# cc13x2_cc26x2 register map
File version: 2.1
CPU: CM4 r0p1, little endian, MPU, FPU, 3 interrupt priority bits
Registers are 32-bit, read-write, reset 0x0 unless marked. A register's access mark holds for its fields unless they carry their own. Offsets are from the block's base; [hi:lo] are bit positions; {n}, {i} and the like mark numbered series; 'fields as' and 'values as' point back to an identical list.

## AUX_DDI0_OSC — Digital to Digital Interface his is a generic module for handling register information between digital core and and digital subchips within the analog domain. o see the actual contents connected on the analog side, please see: DI0: DDI_0_OSC:DDI_0_OSC
Base 0x400CA000
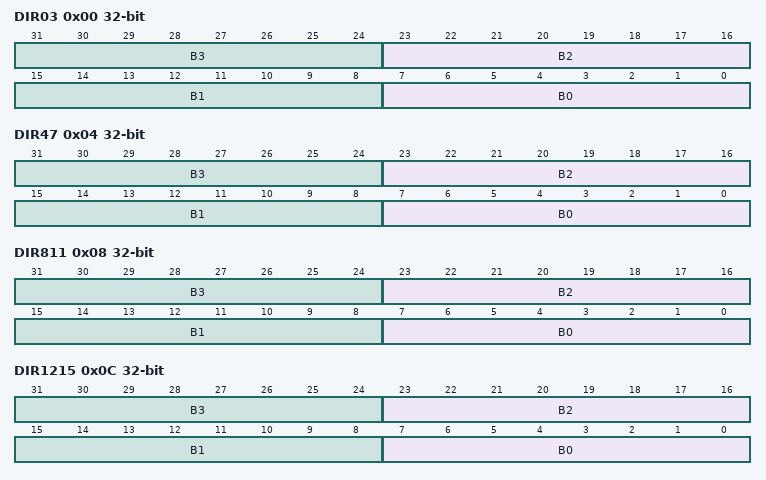
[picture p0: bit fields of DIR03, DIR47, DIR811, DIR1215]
0x00 DIR03 — Direct Access for DDI Byte Offsets 0 to 3
  [8n+7:8n] B{n} (n=0..3)
0x04 DIR47 — Direct Access for DDI Byte Offsets 4 to 7
  [8n+7:8n] B{n} (n=0..3)
0x08 DIR811 — Direct Access for DDI Byte Offsets 8 to 11
  [8n+7:8n] B{n} (n=0..3)
0x0C DIR1215 — Direct Access for DDI Byte Offsets 12 to 15
  [8n+7:8n] B{n} (n=0..3)
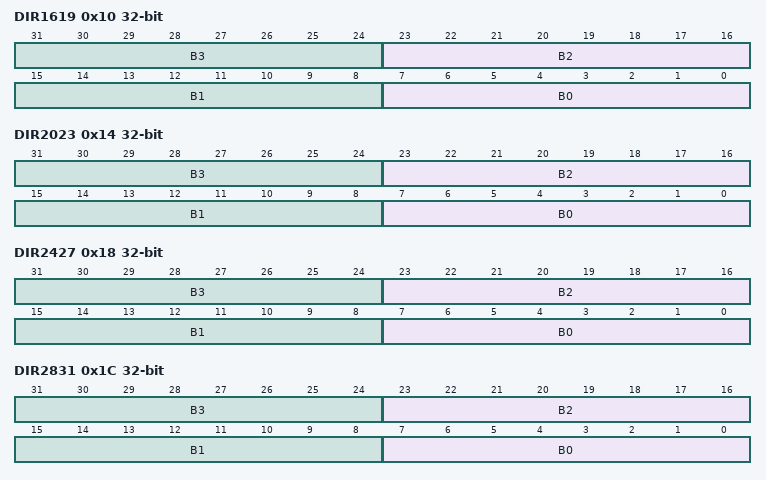
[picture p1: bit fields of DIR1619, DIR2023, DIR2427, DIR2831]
0x10 DIR1619 — Direct Access for DDI Byte Offsets 16 to 19
  [8n+7:8n] B{n} (n=0..3)
0x14 DIR2023 — Direct Access for DDI Byte Offsets 20 to 23
  [8n+7:8n] B{n} (n=0..3)
0x18 DIR2427 — Direct Access for DDI Byte Offsets 24 to 27
  [8n+7:8n] B{n} (n=0..3)
0x1C DIR2831 — Direct Access for DDI Byte Offsets 28 to 31
  [8n+7:8n] B{n} (n=0..3)
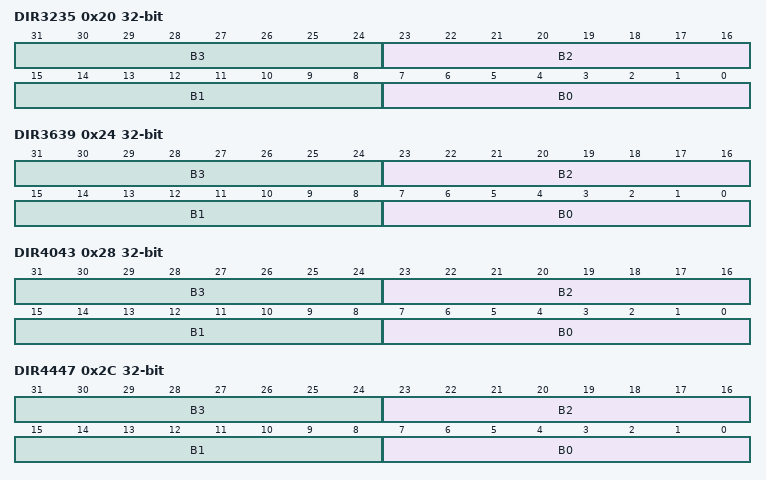
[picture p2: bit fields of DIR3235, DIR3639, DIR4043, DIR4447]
0x20 DIR3235 — Direct Access for DDI Byte Offsets 32 to 35
  [8n+7:8n] B{n} (n=0..3)
0x24 DIR3639 — Direct Access for DDI Byte Offsets 36 to 39
  [8n+7:8n] B{n} (n=0..3)
0x28 DIR4043 — Direct Access for DDI Byte Offsets 40 to 43
  [8n+7:8n] B{n} (n=0..3)
0x2C DIR4447 — Direct Access for DDI Byte Offsets 44 to 47
  [8n+7:8n] B{n} (n=0..3)
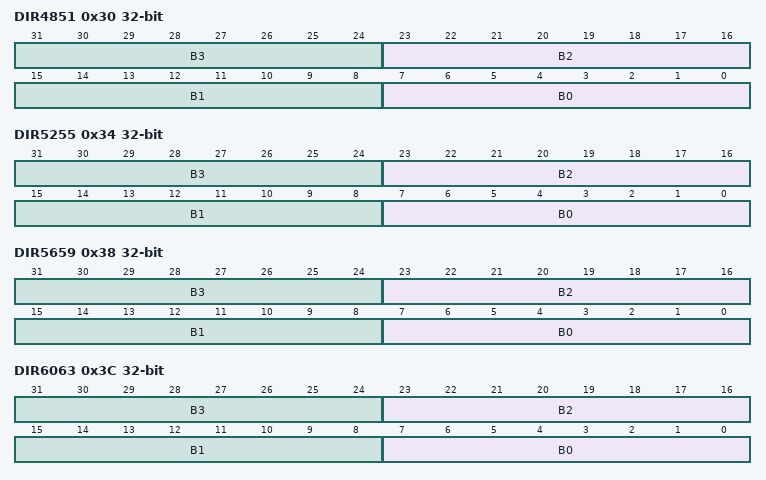
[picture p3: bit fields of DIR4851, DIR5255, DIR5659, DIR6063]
0x30 DIR4851 — Direct Access for DDI Byte Offsets 48 to 51
  [8n+7:8n] B{n} (n=0..3)
0x34 DIR5255 — Direct Access for DDI Byte Offsets 52 to 55
  [8n+7:8n] B{n} (n=0..3)
0x38 DIR5659 — Direct Access for DDI Byte Offsets 56 to 59
  [8n+7:8n] B{n} (n=0..3)
0x3C DIR6063 — Direct Access for DDI Byte Offsets 60 to 63
  [8n+7:8n] B{n} (n=0..3)
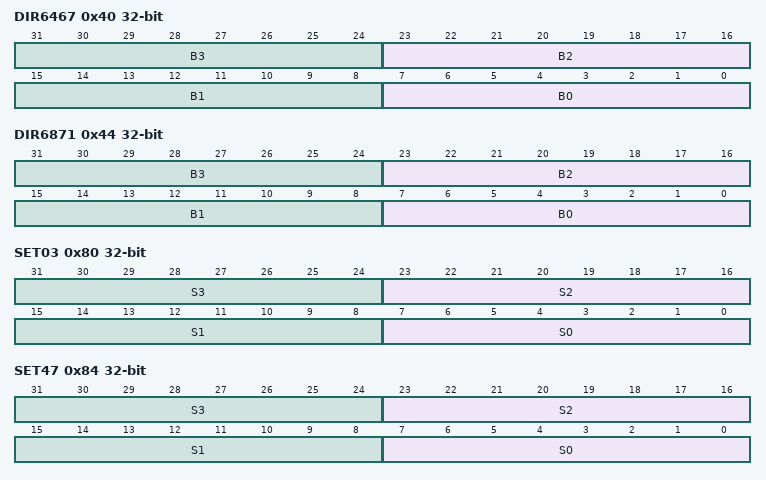
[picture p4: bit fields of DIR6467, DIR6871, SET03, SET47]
0x40 DIR6467 — Direct Access for DDI Byte Offsets 64 to 67
  [8n+7:8n] B{n} (n=0..3)
0x44 DIR6871 — Direct Access for DDI Byte Offsets 68 to 71
  [8n+7:8n] B{n} (n=0..3)
0x80 SET03 wo — Set for DDI Byte Offsets 0 to 3
  [8n+7:8n] S{n} (n=0..3)
0x84 SET47 wo — Set for DDI Byte Offsets 4 to 7
  [8n+7:8n] S{n} (n=0..3)
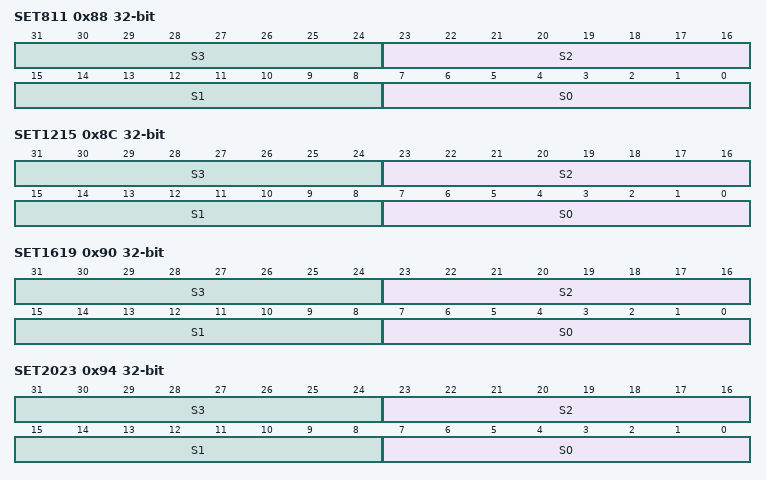
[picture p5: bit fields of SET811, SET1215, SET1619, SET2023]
0x88 SET811 wo — Set for DDI Byte Offsets 8 to 11
  [8n+7:8n] S{n} (n=0..3)
0x8C SET1215 wo — Set for DDI Byte Offsets 12 to 15
  [8n+7:8n] S{n} (n=0..3)
0x90 SET1619 wo — Set for DDI Byte Offsets 16 to 19
  [8n+7:8n] S{n} (n=0..3)
0x94 SET2023 wo — Set for DDI Byte Offsets 20 to 23
  [8n+7:8n] S{n} (n=0..3)
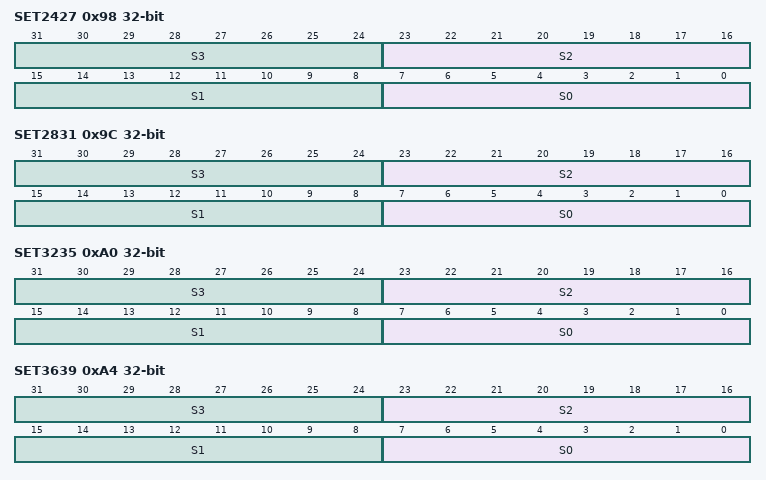
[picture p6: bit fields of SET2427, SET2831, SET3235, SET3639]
0x98 SET2427 wo — Set for DDI Byte Offsets 24 to 27
  [8n+7:8n] S{n} (n=0..3)
0x9C SET2831 wo — Set for DDI Byte Offsets 28 to 31
  [8n+7:8n] S{n} (n=0..3)
0xA0 SET3235 wo — Set for DDI Byte Offsets 32 to 35
  [8n+7:8n] S{n} (n=0..3)
0xA4 SET3639 wo — Set for DDI Byte Offsets 36 to 39
  [8n+7:8n] S{n} (n=0..3)
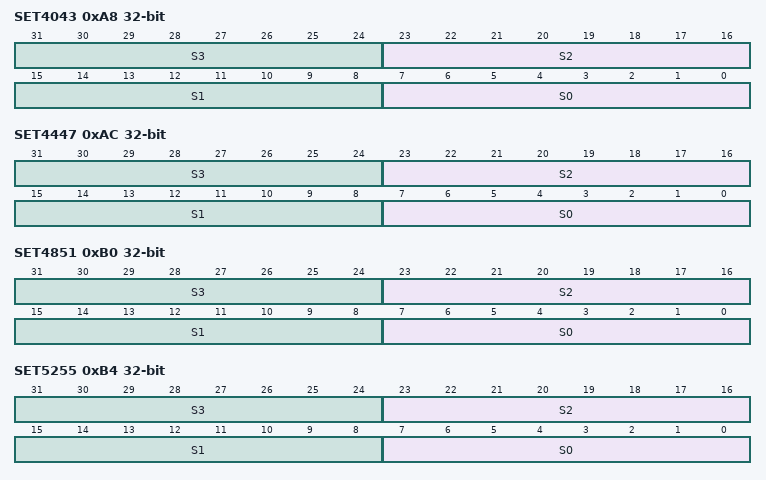
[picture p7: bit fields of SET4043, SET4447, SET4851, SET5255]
0xA8 SET4043 wo — Set for DDI Byte Offsets 40 to 43
  [8n+7:8n] S{n} (n=0..3)
0xAC SET4447 wo — Set for DDI Byte Offsets 44 to 47
  [8n+7:8n] S{n} (n=0..3)
0xB0 SET4851 wo — Set for DDI Byte Offsets 48 to 51
  [8n+7:8n] S{n} (n=0..3)
0xB4 SET5255 wo — Set for DDI Byte Offsets 52 to 55
  [8n+7:8n] S{n} (n=0..3)
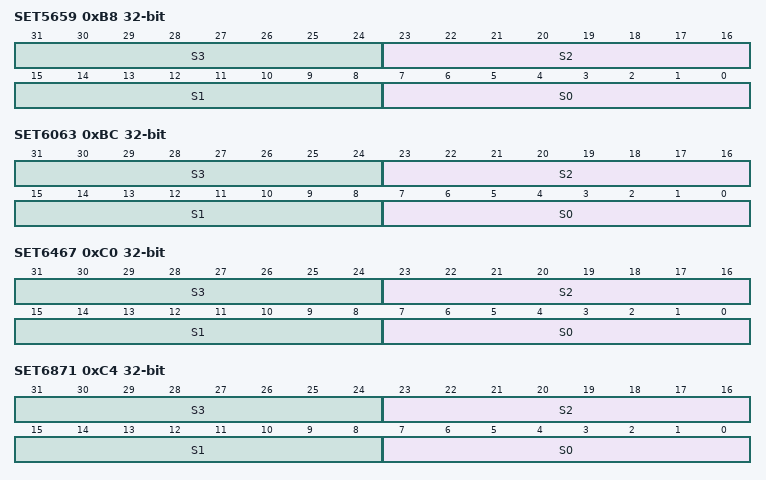
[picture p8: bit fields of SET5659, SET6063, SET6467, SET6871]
0xB8 SET5659 wo — Set for DDI Byte Offsets 56 to 59
  [8n+7:8n] S{n} (n=0..3)
0xBC SET6063 wo — Set for DDI Byte Offsets 60 to 63
  [8n+7:8n] S{n} (n=0..3)
0xC0 SET6467 wo — Set for DDI Byte Offsets 64 to 67
  [8n+7:8n] S{n} (n=0..3)
0xC4 SET6871 wo — Set for DDI Byte Offsets 68 to 71
  [8n+7:8n] S{n} (n=0..3)
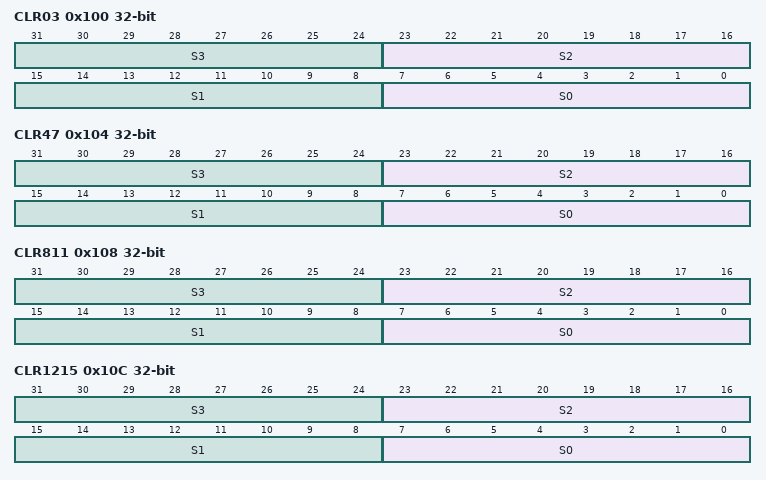
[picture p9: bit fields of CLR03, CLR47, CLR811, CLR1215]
0x100 CLR03 wo — Clear for DDI Byte Offsets 0 to 3
  [8n+7:8n] S{n} (n=0..3)
0x104 CLR47 wo — Clear for DDI Byte Offsets 4 to 7
  [8n+7:8n] S{n} (n=0..3)
0x108 CLR811 wo — Clear for DDI Byte Offsets 8 to 11
  [8n+7:8n] S{n} (n=0..3)
0x10C CLR1215 wo — Clear for DDI Byte Offsets 12 to 15
  [8n+7:8n] S{n} (n=0..3)
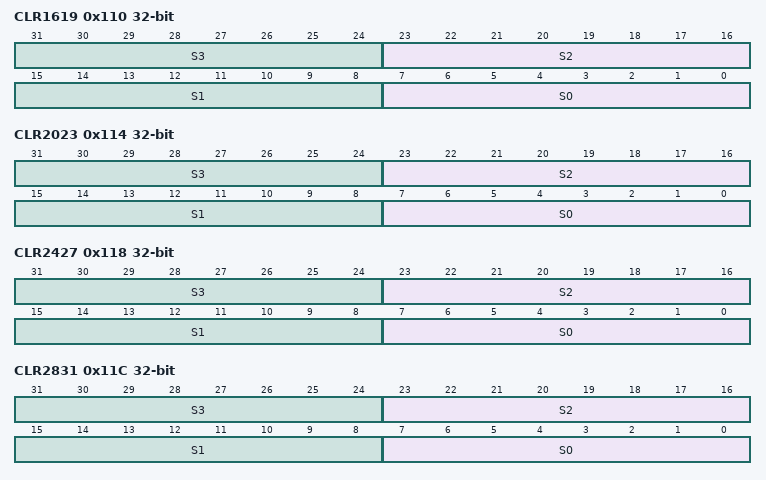
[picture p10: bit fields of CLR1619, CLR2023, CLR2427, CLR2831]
0x110 CLR1619 wo — Clear for DDI Byte Offsets 16 to 19
  [8n+7:8n] S{n} (n=0..3)
0x114 CLR2023 wo — Clear for DDI Byte Offsets 20 to 23
  [8n+7:8n] S{n} (n=0..3)
0x118 CLR2427 wo — Clear for DDI Byte Offsets 24 to 27
  [8n+7:8n] S{n} (n=0..3)
0x11C CLR2831 wo — Clear for DDI Byte Offsets 28 to 31
  [8n+7:8n] S{n} (n=0..3)
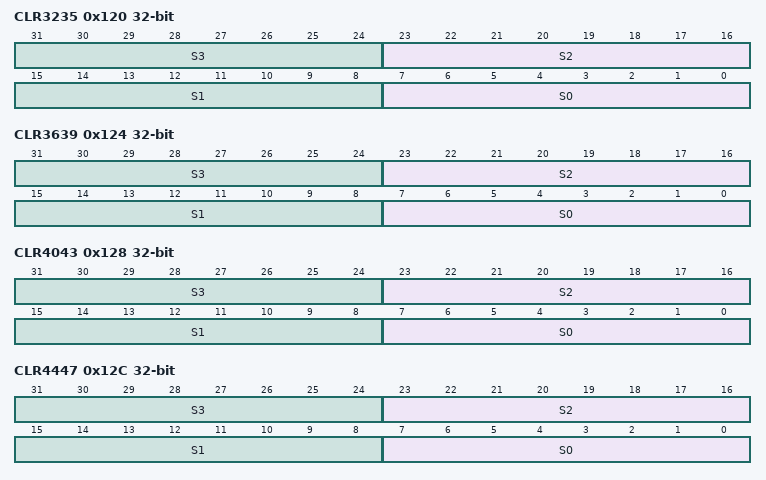
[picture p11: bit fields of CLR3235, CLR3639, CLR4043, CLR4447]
0x120 CLR3235 wo — Clear for DDI Byte Offsets 32 to 35
  [8n+7:8n] S{n} (n=0..3)
0x124 CLR3639 wo — Clear for DDI Byte Offsets 36 to 39
  [8n+7:8n] S{n} (n=0..3)
0x128 CLR4043 wo — Clear for DDI Byte Offsets 40 to 43
  [8n+7:8n] S{n} (n=0..3)
0x12C CLR4447 wo — Clear for DDI Byte Offsets 44 to 47
  [8n+7:8n] S{n} (n=0..3)
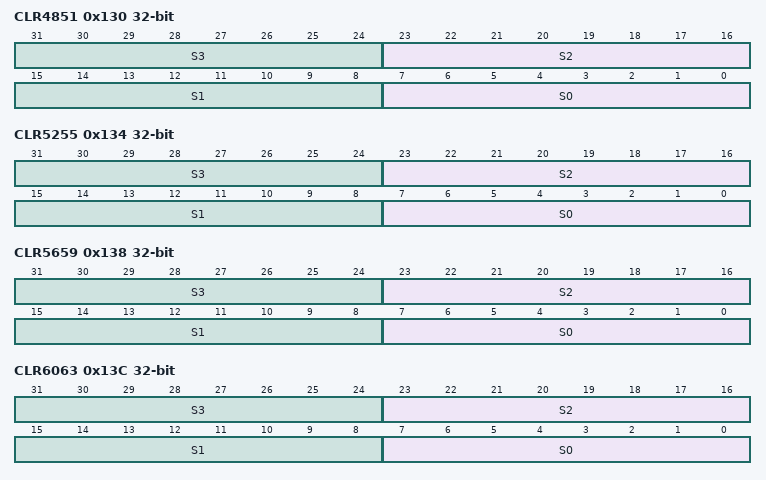
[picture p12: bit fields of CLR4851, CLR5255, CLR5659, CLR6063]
0x130 CLR4851 wo — Clear for DDI Byte Offsets 48 to 51
  [8n+7:8n] S{n} (n=0..3)
0x134 CLR5255 wo — Clear for DDI Byte Offsets 52 to 55
  [8n+7:8n] S{n} (n=0..3)
0x138 CLR5659 wo — Clear for DDI Byte Offsets 56 to 59
  [8n+7:8n] S{n} (n=0..3)
0x13C CLR6063 wo — Clear for DDI Byte Offsets 60 to 63
  [8n+7:8n] S{n} (n=0..3)
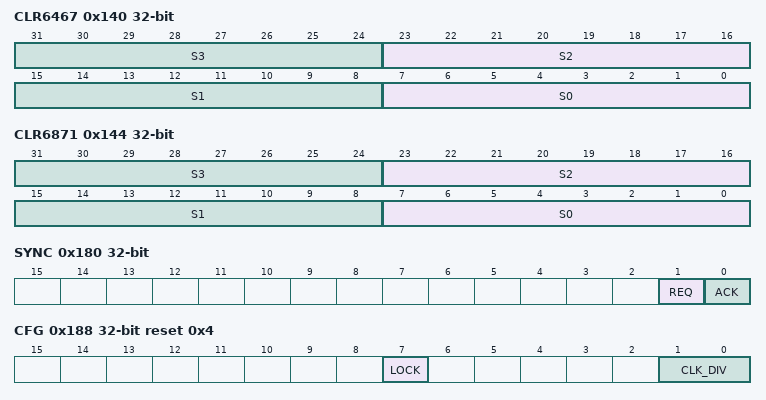
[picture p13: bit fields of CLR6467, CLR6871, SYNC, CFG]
0x140 CLR6467 wo — Clear for DDI Byte Offsets 64 to 67
  [8n+7:8n] S{n} (n=0..3)
0x144 CLR6871 wo — Clear for DDI Byte Offsets 68 to 71
  [8n+7:8n] S{n} (n=0..3)
0x180 SYNC — Internal. Only to be used through TI provided API.
  [1] REQ, [0] ACK
0x188 CFG reset 0x4 — Internal. Only to be used through TI provided API.
  [7] LOCK, [1:0] CLK_DIV
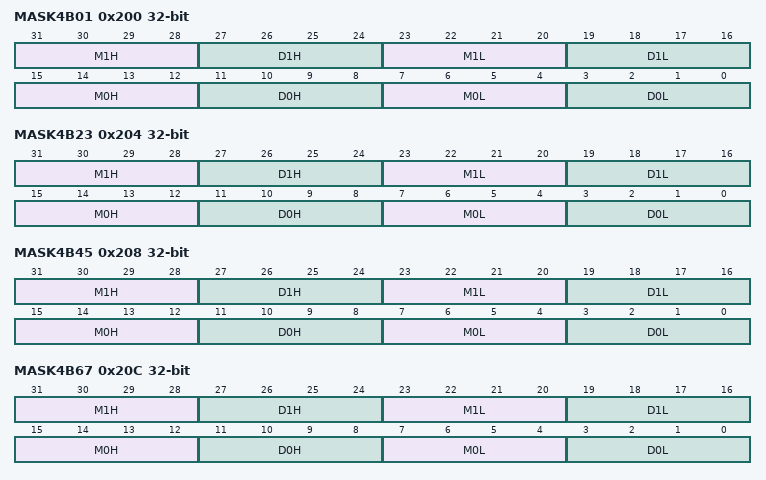
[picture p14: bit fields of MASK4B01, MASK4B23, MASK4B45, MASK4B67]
0x200 MASK4B01 wo — Masked Access (4m/4d), Byte Offsets 0 and 1
  [31:28] M1H, [27:24] D1H, [23:20] M1L, [19:16] D1L, [15:12] M0H, [11:8] D0H, [7:4] M0L, [3:0] D0L
0x204 MASK4B23 wo — Masked Access (4m/4d), Byte Offsets 2 and 3
  fields as MASK4B01
0x208 MASK4B45 wo — Masked Access (4m/4d), Byte Offsets 4 and 5
  fields as MASK4B01
0x20C MASK4B67 wo — Masked Access (4m/4d), Byte Offsets 6 and 7
  fields as MASK4B01
0x210 MASK4B89 wo — Masked Access (4m/4d), Byte Offsets 8 and 9
  fields as MASK4B01
0x214 MASK4B1011 wo — Masked Access (4m/4d), Byte Offsets 10 and 11
  fields as MASK4B01
0x218 MASK4B1213 wo — Masked Access (4m/4d), Byte Offsets 12 and 13
  fields as MASK4B01
0x21C MASK4B1415 wo — Masked Access (4m/4d), Byte Offsets 14 and 15
  fields as MASK4B01
0x220 MASK4B1617 wo — Masked Access (4m/4d), Byte Offsets 16 and 17
  fields as MASK4B01
0x224 MASK4B1819 wo — Masked Access (4m/4d), Byte Offsets 18 and 19
  fields as MASK4B01
0x228 MASK4B2021 wo — Masked Access (4m/4d), Byte Offsets 20 and 21
  fields as MASK4B01
0x22C MASK4B2223 wo — Masked Access (4m/4d), Byte Offsets 22 and 23
  fields as MASK4B01
0x230 MASK4B2425 wo — Masked Access (4m/4d), Byte Offsets 24 and 25
  fields as MASK4B01
0x234 MASK4B2627 wo — Masked Access (4m/4d), Byte Offsets 26 and 27
  fields as MASK4B01
0x238 MASK4B2829 wo — Masked Access (4m/4d), Byte Offsets 28 and 29
  fields as MASK4B01
0x23C MASK4B3031 wo — Masked Access (4m/4d), Byte Offsets 30 and 31
  fields as MASK4B01
0x240 MASK4B3233 wo — Masked Access (4m/4d), Byte Offsets 32 and 33
  fields as MASK4B01
0x244 MASK4B3435 wo — Masked Access (4m/4d), Byte Offsets 34 and 35
  fields as MASK4B01
0x248 MASK4B3637 wo — Masked Access (4m/4d), Byte Offsets 36 and 37
  fields as MASK4B01
0x24C MASK4B3839 wo — Masked Access (4m/4d), Byte Offsets 38 and 39
  fields as MASK4B01
0x250 MASK4B4041 wo — Masked Access (4m/4d), Byte Offsets 40 and 41
  fields as MASK4B01
0x254 MASK4B4243 wo — Masked Access (4m/4d), Byte Offsets 42 and 43
  fields as MASK4B01
0x258 MASK4B4445 wo — Masked Access (4m/4d), Byte Offsets 44 and 45
  fields as MASK4B01
0x25C MASK4B4647 wo — Masked Access (4m/4d), Byte Offsets 46 and 47
  fields as MASK4B01
0x260 MASK4B4849 wo — Masked Access (4m/4d), Byte Offsets 48 and 49
  fields as MASK4B01
0x264 MASK4B5051 wo — Masked Access (4m/4d), Byte Offsets 50 and 51
  fields as MASK4B01
0x268 MASK4B5253 wo — Masked Access (4m/4d), Byte Offsets 52 and 53
  fields as MASK4B01
0x26C MASK4B5455 wo — Masked Access (4m/4d), Byte Offsets 54 and 55
  fields as MASK4B01
0x270 MASK4B5657 wo — Masked Access (4m/4d), Byte Offsets 56 and 57
  fields as MASK4B01
0x274 MASK4B5859 wo — Masked Access (4m/4d), Byte Offsets 58 and 59
  fields as MASK4B01
0x278 MASK4B6061 wo — Masked Access (4m/4d), Byte Offsets 60 and 61
  fields as MASK4B01
0x27C MASK4B6263 wo — Masked Access (4m/4d), Byte Offsets 62 and 63
  fields as MASK4B01
0x280 MASK4B6465 wo — Masked Access (4m/4d), Byte Offsets 64 and 65
  fields as MASK4B01
0x284 MASK4B6667 wo — Masked Access (4m/4d), Byte Offsets 66 and 67
  fields as MASK4B01
0x288 MASK4B6869 wo — Masked Access (4m/4d), Byte Offsets 68 and 69
  fields as MASK4B01
0x28C MASK4B7071 wo — Masked Access (4m/4d), Byte Offsets 70 and 71
  fields as MASK4B01
0x300 MASK8B01 wo — Masked Access (8m/8d), Byte Offsets 0 and 1
  [31:24] M1, [23:16] D1, [15:8] M0, [7:0] D0
0x304 MASK8B23 wo — Masked Access (8m/8d), Byte Offsets 2 and 3
  [31:24] M1, [23:16] D1, [15:8] M0, [7:0] D0
0x308 MASK8B45 wo — Masked Access (8m/8d), Byte Offsets 4 and 5
  [31:24] M1, [23:16] D1, [15:8] M0, [7:0] D0
0x30C MASK8B67 wo — Masked Access (8m/8d), Byte Offsets 6 and 7
  [31:24] M1, [23:16] D1, [15:8] M0, [7:0] D0
0x310 MASK8B89 wo — Masked Access (8m/8d), Byte Offsets 8 and 9
  [31:24] M1, [23:16] D1, [15:8] M0, [7:0] D0
0x314 MASK8B1011 wo — Masked Access (8m/8d), Byte Offsets 10 and 11
  [31:24] M1, [23:16] D1, [15:8] M0, [7:0] D0
0x318 MASK8B1213 wo — Masked Access (8m/8d), Byte Offsets 12 and 13
  [31:24] M1, [23:16] D1, [15:8] M0, [7:0] D0
0x31C MASK8B1415 wo — Masked Access (8m/8d), Byte Offsets 14 and 15
  [31:24] M1, [23:16] D1, [15:8] M0, [7:0] D0
0x320 MASK8B1617 wo — Masked Access (8m/8d), Byte Offsets 16 and 17
  [31:24] M1, [23:16] D1, [15:8] M0, [7:0] D0
0x324 MASK8B1819 wo — Masked Access (8m/8d), Byte Offsets 18 and 19
  [31:24] M1, [23:16] D1, [15:8] M0, [7:0] D0
0x328 MASK8B2021 wo — Masked Access (8m/8d), Byte Offsets 20 and 21
  [31:24] M1, [23:16] D1, [15:8] M0, [7:0] D0
0x32C MASK8B2223 wo — Masked Access (8m/8d), Byte Offsets 22 and 23
  [31:24] M1, [23:16] D1, [15:8] M0, [7:0] D0
0x330 MASK8B2425 wo — Masked Access (8m/8d), Byte Offsets 24 and 25
  [31:24] M1, [23:16] D1, [15:8] M0, [7:0] D0
0x334 MASK8B2627 wo — Masked Access (8m/8d), Byte Offsets 26 and 27
  [31:24] M1, [23:16] D1, [15:8] M0, [7:0] D0
0x338 MASK8B2829 wo — Masked Access (8m/8d), Byte Offsets 28 and 29
  [31:24] M1, [23:16] D1, [15:8] M0, [7:0] D0
0x33C MASK8B3031 wo — Masked Access (8m/8d), Byte Offsets 30 and 31
  [31:24] M1, [23:16] D1, [15:8] M0, [7:0] D0
0x340 MASK8B3233 wo — Masked Access (8m/8d), Byte Offsets 32 and 33
  [31:24] M1, [23:16] D1, [15:8] M0, [7:0] D0
0x344 MASK8B3435 wo — Masked Access (8m/8d), Byte Offsets 34 and 35
  [31:24] M1, [23:16] D1, [15:8] M0, [7:0] D0
0x348 MASK8B3637 wo — Masked Access (8m/8d), Byte Offsets 36 and 37
  [31:24] M1, [23:16] D1, [15:8] M0, [7:0] D0
0x34C MASK8B3839 wo — Masked Access (8m/8d), Byte Offsets 38 and 39
  [31:24] M1, [23:16] D1, [15:8] M0, [7:0] D0
0x350 MASK8B4041 wo — Masked Access (8m/8d), Byte Offsets 40 and 41
  [31:24] M1, [23:16] D1, [15:8] M0, [7:0] D0
0x354 MASK8B4243 wo — Masked Access (8m/8d), Byte Offsets 42 and 43
  [31:24] M1, [23:16] D1, [15:8] M0, [7:0] D0
0x358 MASK8B4445 wo — Masked Access (8m/8d), Byte Offsets 44 and 45
  [31:24] M1, [23:16] D1, [15:8] M0, [7:0] D0
0x35C MASK8B4647 wo — Masked Access (8m/8d), Byte Offsets 46 and 47
  [31:24] M1, [23:16] D1, [15:8] M0, [7:0] D0
0x360 MASK8B4849 wo — Masked Access (8m/8d), Byte Offsets 48 and 49
  [31:24] M1, [23:16] D1, [15:8] M0, [7:0] D0
0x364 MASK8B5051 wo — Masked Access (8m/8d), Byte Offsets 50 and 51
  [31:24] M1, [23:16] D1, [15:8] M0, [7:0] D0
0x368 MASK8B5253 wo — Masked Access (8m/8d), Byte Offsets 52 and 53
  [31:24] M1, [23:16] D1, [15:8] M0, [7:0] D0
0x36C MASK8B5455 wo — Masked Access (8m/8d), Byte Offsets 54 and 55
  [31:24] M1, [23:16] D1, [15:8] M0, [7:0] D0
0x370 MASK8B5657 wo — Masked Access (8m/8d), Byte Offsets 56 and 57
  [31:24] M1, [23:16] D1, [15:8] M0, [7:0] D0
0x374 MASK8B5859 wo — Masked Access (8m/8d), Byte Offsets 58 and 59
  [31:24] M1, [23:16] D1, [15:8] M0, [7:0] D0
0x378 MASK8B6061 wo — Masked Access (8m/8d), Byte Offsets 60 and 61
  [31:24] M1, [23:16] D1, [15:8] M0, [7:0] D0
0x37C MASK8B6263 wo — Masked Access (8m/8d), Byte Offsets 62 and 63
  [31:24] M1, [23:16] D1, [15:8] M0, [7:0] D0
0x380 MASK8B6465 wo — Masked Access (8m/8d), Byte Offsets 64 and 65
  [31:24] M1, [23:16] D1, [15:8] M0, [7:0] D0
0x384 MASK8B6667 wo — Masked Access (8m/8d), Byte Offsets 66 and 67
  [31:24] M1, [23:16] D1, [15:8] M0, [7:0] D0
0x388 MASK8B6869 wo — Masked Access (8m/8d), Byte Offsets 68 and 69
  [31:24] M1, [23:16] D1, [15:8] M0, [7:0] D0
0x38C MASK8B7071 wo — Masked Access (8m/8d), Byte Offsets 70 and 71
  [31:24] M1, [23:16] D1, [15:8] M0, [7:0] D0
0x400 MASK16B01 wo — Masked Access (16m/16d), Byte Offsets 0 and 1
  [31:16] M, [15:0] D
0x404 MASK16B23 wo — Masked Access (16m/16d), Byte Offsets 2 and 3
  [31:16] M, [15:0] D
0x408 MASK16B45 wo — Masked Access (16m/16d), Byte Offsets 4 and 5
  [31:16] M, [15:0] D
0x40C MASK16B67 wo — Masked Access (16m/16d), Byte Offsets 6 and 7
  [31:16] M, [15:0] D
0x410 MASK16B89 wo — Masked Access (16m/16d), Byte Offsets 8 and 9
  [31:16] M, [15:0] D
0x414 MASK16B1011 wo — Masked Access (16m/16d), Byte Offsets 10 and 11
  [31:16] M, [15:0] D
0x418 MASK16B1213 wo — Masked Access (16m/16d), Byte Offsets 12 and 13
  [31:16] M, [15:0] D
0x41C MASK16B1415 wo — Masked Access (16m/16d), Byte Offsets 14 and 15
  [31:16] M, [15:0] D
0x420 MASK16B1617 wo — Masked Access (16m/16d), Byte Offsets 16 and 17
  [31:16] M, [15:0] D
0x424 MASK16B1819 wo — Masked Access (16m/16d), Byte Offsets 18 and 19
  [31:16] M, [15:0] D
0x428 MASK16B2021 wo — Masked Access (16m/16d), Byte Offsets 20 and 21
  [31:16] M, [15:0] D
0x42C MASK16B2223 wo — Masked Access (16m/16d), Byte Offsets 22 and 23
  [31:16] M, [15:0] D
0x430 MASK16B2425 wo — Masked Access (16m/16d), Byte Offsets 24 and 25
  [31:16] M, [15:0] D
0x434 MASK16B2627 wo — Masked Access (16m/16d), Byte Offsets 26 and 27
  [31:16] M, [15:0] D
0x438 MASK16B2829 wo — Masked Access (16m/16d), Byte Offsets 28 and 29
  [31:16] M, [15:0] D
0x43C MASK16B3031 wo — Masked Access (16m/16d), Byte Offsets 30 and 31
  [31:16] M, [15:0] D
0x440 MASK16B3233 wo — Masked Access (16m/16d), Byte Offsets 32 and 33
  [31:16] M, [15:0] D
0x444 MASK16B3435 wo — Masked Access (16m/16d), Byte Offsets 34 and 35
  [31:16] M, [15:0] D
0x448 MASK16B3637 wo — Masked Access (16m/16d), Byte Offsets 36 and 37
  [31:16] M, [15:0] D
0x44C MASK16B3839 wo — Masked Access (16m/16d), Byte Offsets 38 and 39
  [31:16] M, [15:0] D
0x450 MASK16B4041 wo — Masked Access (16m/16d), Byte Offsets 40 and 41
  [31:16] M, [15:0] D
0x454 MASK16B4243 wo — Masked Access (16m/16d), Byte Offsets 42 and 43
  [31:16] M, [15:0] D
0x458 MASK16B4445 wo — Masked Access (16m/16d), Byte Offsets 44 and 45
  [31:16] M, [15:0] D
0x45C MASK16B4647 wo — Masked Access (16m/16d), Byte Offsets 46 and 47
  [31:16] M, [15:0] D
0x460 MASK16B4849 wo — Masked Access (16m/16d), Byte Offsets 48 and 49
  [31:16] M, [15:0] D
0x464 MASK16B5051 wo — Masked Access (16m/16d), Byte Offsets 50 and 51
  [31:16] M, [15:0] D
0x468 MASK16B5253 wo — Masked Access (16m/16d), Byte Offsets 52 and 53
  [31:16] M, [15:0] D
0x46C MASK16B5455 wo — Masked Access (16m/16d), Byte Offsets 54 and 55
  [31:16] M, [15:0] D
0x470 MASK16B5657 wo — Masked Access (16m/16d), Byte Offsets 56 and 57
  [31:16] M, [15:0] D
0x474 MASK16B5859 wo — Masked Access (16m/16d), Byte Offsets 58 and 59
  [31:16] M, [15:0] D
0x478 MASK16B6061 wo — Masked Access (16m/16d), Byte Offsets 60 and 61
  [31:16] M, [15:0] D
0x47C MASK16B6263 wo — Masked Access (16m/16d), Byte Offsets 62 and 63
  [31:16] M, [15:0] D
0x480 MASK16B6465 wo — Masked Access (16m/16d), Byte Offsets 64 and 65
  [31:16] M, [15:0] D
0x484 MASK16B6667 wo — Masked Access (16m/16d), Byte Offsets 66 and 67
  [31:16] M, [15:0] D
0x488 MASK16B6869 wo — Masked Access (16m/16d), Byte Offsets 68 and 69
  [31:16] M, [15:0] D
0x48C MASK16B7071 wo — Masked Access (16m/16d), Byte Offsets 70 and 71
  [31:16] M, [15:0] D
